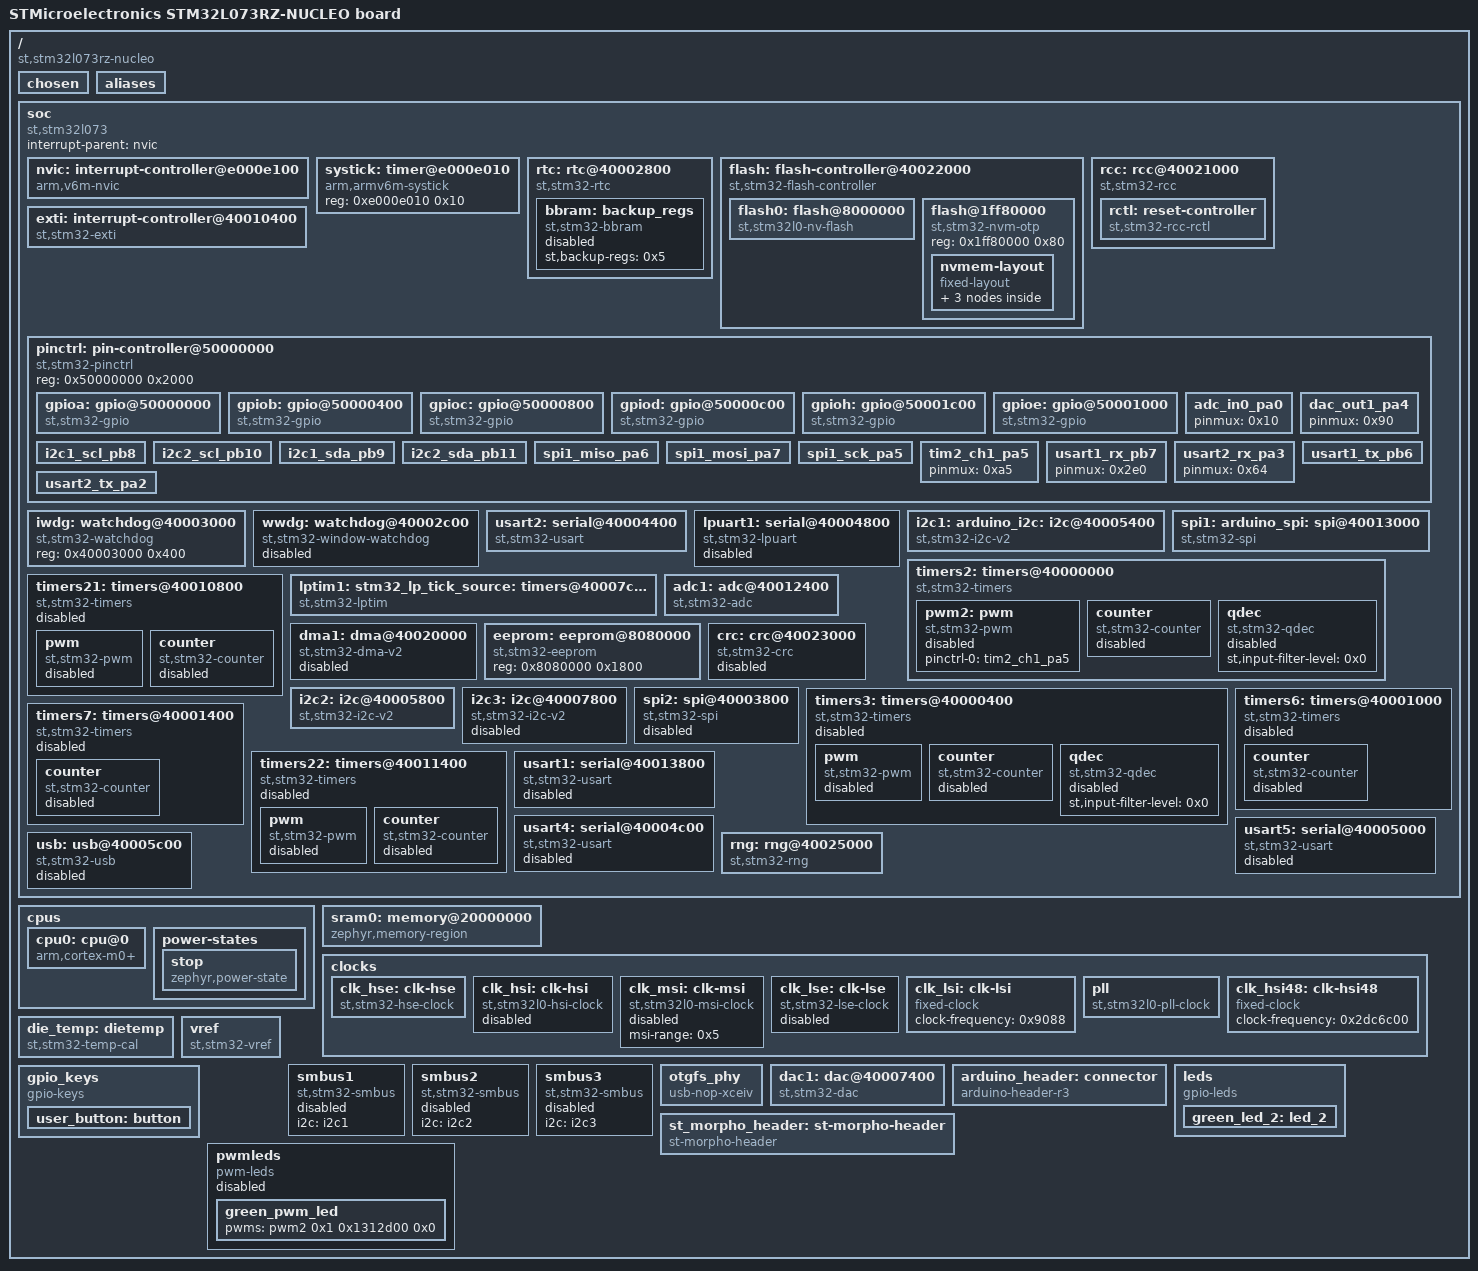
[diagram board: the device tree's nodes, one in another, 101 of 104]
/dts-v1/;

/* node '/' defined in zephyr/dts/common/skeleton.dtsi:9 */
/ {
	#address-cells = < 0x1 >;                              /* in zephyr/dts/common/skeleton.dtsi:10 */
	#size-cells = < 0x1 >;                                 /* in zephyr/dts/common/skeleton.dtsi:11 */
	model = "STMicroelectronics STM32L073RZ-NUCLEO board"; /* in zephyr/boards/st/nucleo_l073rz/nucleo_l073rz.dts:16 */
	compatible = "st,stm32l073rz-nucleo";                  /* in zephyr/boards/st/nucleo_l073rz/nucleo_l073rz.dts:17 */

	/* node '/chosen' defined in zephyr/dts/common/skeleton.dtsi:13 */
	chosen {
		zephyr,crc = &crc;                /* in zephyr/dts/arm/st/l0/stm32l0.dtsi:23 */
		zephyr,flash-controller = &flash; /* in zephyr/dts/arm/st/l0/stm32l0.dtsi:24 */
		zephyr,entropy = &rng;            /* in zephyr/dts/arm/st/l0/stm32l072.dtsi:11 */
		zephyr,console = &usart2;         /* in zephyr/boards/st/nucleo_l073rz/nucleo_l073rz.dts:20 */
		zephyr,shell-uart = &usart2;      /* in zephyr/boards/st/nucleo_l073rz/nucleo_l073rz.dts:21 */
		zephyr,sram = &sram0;             /* in zephyr/boards/st/nucleo_l073rz/nucleo_l073rz.dts:22 */
		zephyr,flash = &flash0;           /* in zephyr/boards/st/nucleo_l073rz/nucleo_l073rz.dts:23 */
	};

	/* node '/aliases' defined in zephyr/dts/common/skeleton.dtsi:15 */
	aliases {
		led0 = &green_led_2;       /* in zephyr/boards/st/nucleo_l073rz/nucleo_l073rz.dts:56 */
		sw0 = &user_button;        /* in zephyr/boards/st/nucleo_l073rz/nucleo_l073rz.dts:57 */
		pwm-led0 = &green_pwm_led; /* in zephyr/boards/st/nucleo_l073rz/nucleo_l073rz.dts:58 */
		watchdog0 = &iwdg;         /* in zephyr/boards/st/nucleo_l073rz/nucleo_l073rz.dts:59 */
		eeprom-0 = &eeprom;        /* in zephyr/boards/st/nucleo_l073rz/nucleo_l073rz.dts:60 */
		die-temp0 = &die_temp;     /* in zephyr/boards/st/nucleo_l073rz/nucleo_l073rz.dts:61 */
		volt-sensor0 = &vref;      /* in zephyr/boards/st/nucleo_l073rz/nucleo_l073rz.dts:62 */
	};

	/* node '/soc' defined in zephyr/dts/arm/armv6-m.dtsi:6 */
	soc {
		#address-cells = < 0x1 >;     /* in zephyr/dts/arm/armv6-m.dtsi:7 */
		#size-cells = < 0x1 >;        /* in zephyr/dts/arm/armv6-m.dtsi:8 */
		interrupt-parent = < &nvic >; /* in zephyr/dts/arm/armv6-m.dtsi:10 */
		ranges;                       /* in zephyr/dts/arm/armv6-m.dtsi:11 */
		compatible = "st,stm32l073",
		             "st,stm32l0",
		             "simple-bus";    /* in zephyr/dts/arm/st/l0/stm32l073.dtsi:12 */

		/* node '/soc/interrupt-controller@e000e100' defined in zephyr/dts/arm/armv6-m.dtsi:13 */
		nvic: interrupt-controller@e000e100 {
			#address-cells = < 0x1 >;            /* in zephyr/dts/arm/armv6-m.dtsi:14 */
			compatible = "arm,v6m-nvic";         /* in zephyr/dts/arm/armv6-m.dtsi:15 */
			reg = < 0xe000e100 0xc00 >;          /* in zephyr/dts/arm/armv6-m.dtsi:16 */
			interrupt-controller;                /* in zephyr/dts/arm/armv6-m.dtsi:17 */
			#interrupt-cells = < 0x2 >;          /* in zephyr/dts/arm/armv6-m.dtsi:18 */
			arm,num-irq-priority-bits = < 0x2 >; /* in zephyr/dts/arm/st/l0/stm32l0.dtsi:429 */
			phandle = < 0x1 >;                   /* in zephyr/dts/arm/armv6-m.dtsi:10 */
		};

		/* node '/soc/timer@e000e010' defined in zephyr/dts/arm/armv6-m.dtsi:21 */
		systick: timer@e000e010 {
			compatible = "arm,armv6m-systick"; /* in zephyr/dts/arm/armv6-m.dtsi:22 */
			reg = < 0xe000e010 0x10 >;         /* in zephyr/dts/arm/armv6-m.dtsi:23 */
		};

		/* node '/soc/rtc@40002800' defined in zephyr/dts/arm/st/l0/stm32l0.dtsi:98 */
		rtc: rtc@40002800 {
			compatible = "st,stm32-rtc";       /* in zephyr/dts/arm/st/l0/stm32l0.dtsi:99 */
			reg = < 0x40002800 0x400 >;        /* in zephyr/dts/arm/st/l0/stm32l0.dtsi:100 */
			interrupts = < 0x2 0x0 >;          /* in zephyr/dts/arm/st/l0/stm32l0.dtsi:101 */
			prescaler = < 0x8000 >;            /* in zephyr/dts/arm/st/l0/stm32l0.dtsi:103 */
			alarms-count = < 0x2 >;            /* in zephyr/dts/arm/st/l0/stm32l0.dtsi:104 */
			alrm-exti-line = < 0x11 >;         /* in zephyr/dts/arm/st/l0/stm32l0.dtsi:105 */
			clocks = < &rcc 0x38 0x10000000 >,
			         < &rcc 0x3 0x2300050 >;   /* in zephyr/boards/st/nucleo_l073rz/nucleo_l073rz.dts:172 */
			status = "okay";                   /* in zephyr/boards/st/nucleo_l073rz/nucleo_l073rz.dts:174 */

			/* node '/soc/rtc@40002800/backup_regs' defined in zephyr/dts/arm/st/l0/stm32l0.dtsi:108 */
			bbram: backup_regs {
				compatible = "st,stm32-bbram"; /* in zephyr/dts/arm/st/l0/stm32l0.dtsi:109 */
				st,backup-regs = < 0x5 >;      /* in zephyr/dts/arm/st/l0/stm32l0.dtsi:110 */
				status = "disabled";           /* in zephyr/dts/arm/st/l0/stm32l0.dtsi:111 */
			};
		};

		/* node '/soc/flash-controller@40022000' defined in zephyr/dts/arm/st/l0/stm32l0.dtsi:115 */
		flash: flash-controller@40022000 {
			compatible = "st,stm32-flash-controller",
			             "st,stm32f1-flash-controller"; /* in zephyr/dts/arm/st/l0/stm32l0.dtsi:116 */
			reg = < 0x40022000 0x400 >;                 /* in zephyr/dts/arm/st/l0/stm32l0.dtsi:117 */
			interrupts = < 0x3 0x0 >;                   /* in zephyr/dts/arm/st/l0/stm32l0.dtsi:118 */
			#address-cells = < 0x1 >;                   /* in zephyr/dts/arm/st/l0/stm32l0.dtsi:120 */
			#size-cells = < 0x1 >;                      /* in zephyr/dts/arm/st/l0/stm32l0.dtsi:121 */

			/* node '/soc/flash-controller@40022000/flash@8000000' defined in zephyr/dts/arm/st/l0/stm32l0.dtsi:123 */
			flash0: flash@8000000 {
				compatible = "st,stm32l0-nv-flash",
				             "st,stm32-nv-flash",
				             "soc-nv-flash";        /* in zephyr/dts/arm/st/l0/stm32l0.dtsi:124 */
				write-block-size = < 0x4 >;         /* in zephyr/dts/arm/st/l0/stm32l0.dtsi:127 */
				max-erase-time = < 0x4 >;           /* in zephyr/dts/arm/st/l0/stm32l0.dtsi:129 */
				reg = < 0x8000000 0x30000 >;        /* in zephyr/dts/arm/st/l0/stm32l073Xz.dtsi:17 */
			};

			/* node '/soc/flash-controller@40022000/flash@1ff80000' defined in zephyr/dts/arm/st/l0/stm32l0.dtsi:141 */
			flash@1ff80000 {
				compatible = "st,stm32-nvm-otp"; /* in zephyr/dts/arm/st/l0/stm32l0.dtsi:142 */
				reg = < 0x1ff80000 0x80 >;       /* in zephyr/dts/arm/st/l0/stm32l0.dtsi:143 */

				/* node '/soc/flash-controller@40022000/flash@1ff80000/nvmem-layout' defined in zephyr/dts/arm/st/l0/stm32l0.dtsi:145 */
				nvmem-layout {
					compatible = "fixed-layout"; /* in zephyr/dts/arm/st/l0/stm32l0.dtsi:146 */
					#address-cells = < 0x1 >;    /* in zephyr/dts/arm/st/l0/stm32l0.dtsi:147 */
					#size-cells = < 0x1 >;       /* in zephyr/dts/arm/st/l0/stm32l0.dtsi:148 */

					/* node '/soc/flash-controller@40022000/flash@1ff80000/nvmem-layout/vrefint@78' defined in zephyr/dts/arm/st/l0/stm32l0.dtsi:150 */
					vrefint_otp: vrefint@78 {
						reg = < 0x78 0x2 >;          /* in zephyr/dts/arm/st/l0/stm32l0.dtsi:151 */
						#nvmem-cell-cells = < 0x0 >; /* in zephyr/dts/arm/st/l0/stm32l0.dtsi:152 */
						read-only;                   /* in zephyr/dts/arm/st/l0/stm32l0.dtsi:153 */
						phandle = < 0x18 >;          /* in zephyr/dts/arm/st/l0/stm32l0.dtsi:413 */
					};

					/* node '/soc/flash-controller@40022000/flash@1ff80000/nvmem-layout/ts-cal1@7a' defined in zephyr/dts/arm/st/l0/stm32l0.dtsi:156 */
					ts_cal1_otp: ts-cal1@7a {
						reg = < 0x7a 0x2 >;          /* in zephyr/dts/arm/st/l0/stm32l0.dtsi:157 */
						#nvmem-cell-cells = < 0x0 >; /* in zephyr/dts/arm/st/l0/stm32l0.dtsi:158 */
						read-only;                   /* in zephyr/dts/arm/st/l0/stm32l0.dtsi:159 */
						phandle = < 0x15 >;          /* in zephyr/dts/arm/st/l0/stm32l0.dtsi:402 */
					};

					/* node '/soc/flash-controller@40022000/flash@1ff80000/nvmem-layout/ts-cal2@7e' defined in zephyr/dts/arm/st/l0/stm32l0.dtsi:162 */
					ts_cal2_otp: ts-cal2@7e {
						reg = < 0x7e 0x2 >;          /* in zephyr/dts/arm/st/l0/stm32l0.dtsi:163 */
						#nvmem-cell-cells = < 0x0 >; /* in zephyr/dts/arm/st/l0/stm32l0.dtsi:164 */
						read-only;                   /* in zephyr/dts/arm/st/l0/stm32l0.dtsi:165 */
						phandle = < 0x16 >;          /* in zephyr/dts/arm/st/l0/stm32l0.dtsi:402 */
					};
				};
			};
		};

		/* node '/soc/rcc@40021000' defined in zephyr/dts/arm/st/l0/stm32l0.dtsi:171 */
		rcc: rcc@40021000 {
			compatible = "st,stm32-rcc";     /* in zephyr/dts/arm/st/l0/stm32l0.dtsi:172 */
			#clock-cells = < 0x2 >;          /* in zephyr/dts/arm/st/l0/stm32l0.dtsi:173 */
			reg = < 0x40021000 0x400 >;      /* in zephyr/dts/arm/st/l0/stm32l0.dtsi:174 */
			clocks = < &pll >;               /* in zephyr/boards/st/nucleo_l073rz/nucleo_l073rz.dts:88 */
			clock-frequency = < 0x1e84800 >; /* in zephyr/boards/st/nucleo_l073rz/nucleo_l073rz.dts:89 */
			ahb-prescaler = < 0x1 >;         /* in zephyr/boards/st/nucleo_l073rz/nucleo_l073rz.dts:90 */
			apb1-prescaler = < 0x1 >;        /* in zephyr/boards/st/nucleo_l073rz/nucleo_l073rz.dts:91 */
			apb2-prescaler = < 0x1 >;        /* in zephyr/boards/st/nucleo_l073rz/nucleo_l073rz.dts:92 */
			phandle = < 0x2 >;               /* in zephyr/boards/st/nucleo_l073rz/nucleo_l073rz.dts:172 */

			/* node '/soc/rcc@40021000/reset-controller' defined in zephyr/dts/arm/st/l0/stm32l0.dtsi:176 */
			rctl: reset-controller {
				compatible = "st,stm32-rcc-rctl"; /* in zephyr/dts/arm/st/l0/stm32l0.dtsi:177 */
				#reset-cells = < 0x1 >;           /* in zephyr/dts/arm/st/l0/stm32l0.dtsi:178 */
				phandle = < 0x4 >;                /* in zephyr/dts/arm/st/l0/stm32l0.dtsi:260 */
			};
		};

		/* node '/soc/interrupt-controller@40010400' defined in zephyr/dts/arm/st/l0/stm32l0.dtsi:182 */
		exti: interrupt-controller@40010400 {
			compatible = "st,stm32-exti"; /* in zephyr/dts/arm/st/l0/stm32l0.dtsi:183 */
			interrupt-controller;         /* in zephyr/dts/arm/st/l0/stm32l0.dtsi:184 */
			#interrupt-cells = < 0x1 >;   /* in zephyr/dts/arm/st/l0/stm32l0.dtsi:185 */
			#address-cells = < 0x0 >;     /* in zephyr/dts/arm/st/l0/stm32l0.dtsi:186 */
			reg = < 0x40010400 0x400 >;   /* in zephyr/dts/arm/st/l0/stm32l0.dtsi:187 */
			clocks = < &rcc 0x34 0x1 >;   /* in zephyr/dts/arm/st/l0/stm32l0.dtsi:188 */
			num-lines = < 0x20 >;         /* in zephyr/dts/arm/st/l0/stm32l0.dtsi:189 */
			interrupts = < 0x5 0x0 >,
			             < 0x6 0x0 >,
			             < 0x7 0x0 >;     /* in zephyr/dts/arm/st/l0/stm32l0.dtsi:190 */
			interrupt-names = "line0-1",
			                  "line2-3",
			                  "line4-15"; /* in zephyr/dts/arm/st/l0/stm32l0.dtsi:191 */
			line-ranges = < 0x0 0x2 >,
			              < 0x2 0x2 >,
			              < 0x4 0xc >;    /* in zephyr/dts/arm/st/l0/stm32l0.dtsi:192 */
		};

		/* node '/soc/pin-controller@50000000' defined in zephyr/dts/arm/st/l0/stm32l0.dtsi:195 */
		pinctrl: pin-controller@50000000 {
			compatible = "st,stm32-pinctrl"; /* in zephyr/dts/arm/st/l0/stm32l0.dtsi:196 */
			#address-cells = < 0x1 >;        /* in zephyr/dts/arm/st/l0/stm32l0.dtsi:197 */
			#size-cells = < 0x1 >;           /* in zephyr/dts/arm/st/l0/stm32l0.dtsi:198 */
			reg = < 0x50000000 0x2000 >;     /* in zephyr/dts/arm/st/l0/stm32l0.dtsi:199 */

			/* node '/soc/pin-controller@50000000/gpio@50000000' defined in zephyr/dts/arm/st/l0/stm32l0.dtsi:201 */
			gpioa: gpio@50000000 {
				compatible = "st,stm32-gpio"; /* in zephyr/dts/arm/st/l0/stm32l0.dtsi:202 */
				gpio-controller;              /* in zephyr/dts/arm/st/l0/stm32l0.dtsi:203 */
				#gpio-cells = < 0x2 >;        /* in zephyr/dts/arm/st/l0/stm32l0.dtsi:204 */
				reg = < 0x50000000 0x400 >;   /* in zephyr/dts/arm/st/l0/stm32l0.dtsi:205 */
				clocks = < &rcc 0x2c 0x1 >;   /* in zephyr/dts/arm/st/l0/stm32l0.dtsi:206 */
				phandle = < 0x1d >;           /* in zephyr/boards/st/nucleo_l073rz/arduino_r3_connector.dtsi:15 */
			};

			/* node '/soc/pin-controller@50000000/gpio@50000400' defined in zephyr/dts/arm/st/l0/stm32l0.dtsi:209 */
			gpiob: gpio@50000400 {
				compatible = "st,stm32-gpio"; /* in zephyr/dts/arm/st/l0/stm32l0.dtsi:210 */
				gpio-controller;              /* in zephyr/dts/arm/st/l0/stm32l0.dtsi:211 */
				#gpio-cells = < 0x2 >;        /* in zephyr/dts/arm/st/l0/stm32l0.dtsi:212 */
				reg = < 0x50000400 0x400 >;   /* in zephyr/dts/arm/st/l0/stm32l0.dtsi:213 */
				clocks = < &rcc 0x2c 0x2 >;   /* in zephyr/dts/arm/st/l0/stm32l0.dtsi:214 */
				phandle = < 0x1e >;           /* in zephyr/boards/st/nucleo_l073rz/arduino_r3_connector.dtsi:15 */
			};

			/* node '/soc/pin-controller@50000000/gpio@50000800' defined in zephyr/dts/arm/st/l0/stm32l0.dtsi:217 */
			gpioc: gpio@50000800 {
				compatible = "st,stm32-gpio"; /* in zephyr/dts/arm/st/l0/stm32l0.dtsi:218 */
				gpio-controller;              /* in zephyr/dts/arm/st/l0/stm32l0.dtsi:219 */
				#gpio-cells = < 0x2 >;        /* in zephyr/dts/arm/st/l0/stm32l0.dtsi:220 */
				reg = < 0x50000800 0x400 >;   /* in zephyr/dts/arm/st/l0/stm32l0.dtsi:221 */
				clocks = < &rcc 0x2c 0x4 >;   /* in zephyr/dts/arm/st/l0/stm32l0.dtsi:222 */
				phandle = < 0x1f >;           /* in zephyr/boards/st/nucleo_l073rz/arduino_r3_connector.dtsi:15 */
			};

			/* node '/soc/pin-controller@50000000/gpio@50000c00' defined in zephyr/dts/arm/st/l0/stm32l0.dtsi:225 */
			gpiod: gpio@50000c00 {
				compatible = "st,stm32-gpio"; /* in zephyr/dts/arm/st/l0/stm32l0.dtsi:226 */
				gpio-controller;              /* in zephyr/dts/arm/st/l0/stm32l0.dtsi:227 */
				#gpio-cells = < 0x2 >;        /* in zephyr/dts/arm/st/l0/stm32l0.dtsi:228 */
				reg = < 0x50000c00 0x400 >;   /* in zephyr/dts/arm/st/l0/stm32l0.dtsi:229 */
				clocks = < &rcc 0x2c 0x8 >;   /* in zephyr/dts/arm/st/l0/stm32l0.dtsi:230 */
				phandle = < 0x20 >;           /* in zephyr/boards/st/nucleo_l073rz/st_morpho_connector.dtsi:15 */
			};

			/* node '/soc/pin-controller@50000000/gpio@50001c00' defined in zephyr/dts/arm/st/l0/stm32l0.dtsi:233 */
			gpioh: gpio@50001c00 {
				compatible = "st,stm32-gpio"; /* in zephyr/dts/arm/st/l0/stm32l0.dtsi:234 */
				gpio-controller;              /* in zephyr/dts/arm/st/l0/stm32l0.dtsi:235 */
				#gpio-cells = < 0x2 >;        /* in zephyr/dts/arm/st/l0/stm32l0.dtsi:236 */
				reg = < 0x50001c00 0x400 >;   /* in zephyr/dts/arm/st/l0/stm32l0.dtsi:237 */
				clocks = < &rcc 0x2c 0x80 >;  /* in zephyr/dts/arm/st/l0/stm32l0.dtsi:238 */
				phandle = < 0x21 >;           /* in zephyr/boards/st/nucleo_l073rz/st_morpho_connector.dtsi:15 */
			};

			/* node '/soc/pin-controller@50000000/gpio@50001000' defined in zephyr/dts/arm/st/l0/stm32l071.dtsi:14 */
			gpioe: gpio@50001000 {
				compatible = "st,stm32-gpio"; /* in zephyr/dts/arm/st/l0/stm32l071.dtsi:15 */
				gpio-controller;              /* in zephyr/dts/arm/st/l0/stm32l071.dtsi:16 */
				#gpio-cells = < 0x2 >;        /* in zephyr/dts/arm/st/l0/stm32l071.dtsi:17 */
				reg = < 0x50001000 0x400 >;   /* in zephyr/dts/arm/st/l0/stm32l071.dtsi:18 */
				clocks = < &rcc 0x2c 0x10 >;  /* in zephyr/dts/arm/st/l0/stm32l071.dtsi:19 */
			};

			/* node '/soc/pin-controller@50000000/adc_in0_pa0' defined in modules/hal/stm32/dts/st/l0/stm32l073r(b-z)tx-pinctrl.dtsi:13 */
			adc_in0_pa0: adc_in0_pa0 {
				pinmux = < 0x10 >; /* in modules/hal/stm32/dts/st/l0/stm32l073r(b-z)tx-pinctrl.dtsi:14 */
				phandle = < 0xd >; /* in zephyr/boards/st/nucleo_l073rz/nucleo_l073rz.dts:143 */
			};

			/* node '/soc/pin-controller@50000000/dac_out1_pa4' defined in modules/hal/stm32/dts/st/l0/stm32l073r(b-z)tx-pinctrl.dtsi:365 */
			dac_out1_pa4: dac_out1_pa4 {
				pinmux = < 0x90 >;  /* in modules/hal/stm32/dts/st/l0/stm32l073r(b-z)tx-pinctrl.dtsi:366 */
				phandle = < 0x1c >; /* in zephyr/boards/st/nucleo_l073rz/nucleo_l073rz.dts:156 */
			};

			/* node '/soc/pin-controller@50000000/i2c1_scl_pb8' defined in modules/hal/stm32/dts/st/l0/stm32l073r(b-z)tx-pinctrl.dtsi:387 */
			i2c1_scl_pb8: i2c1_scl_pb8 {
				pinmux = < 0x304 >; /* in modules/hal/stm32/dts/st/l0/stm32l073r(b-z)tx-pinctrl.dtsi:388 */
				bias-pull-up;       /* in modules/hal/stm32/dts/st/l0/stm32l073r(b-z)tx-pinctrl.dtsi:389 */
				drive-open-drain;   /* in modules/hal/stm32/dts/st/l0/stm32l073r(b-z)tx-pinctrl.dtsi:390 */
				phandle = < 0x7 >;  /* in zephyr/boards/st/nucleo_l073rz/nucleo_l073rz.dts:119 */
			};

			/* node '/soc/pin-controller@50000000/i2c2_scl_pb10' defined in modules/hal/stm32/dts/st/l0/stm32l073r(b-z)tx-pinctrl.dtsi:393 */
			i2c2_scl_pb10: i2c2_scl_pb10 {
				pinmux = < 0x346 >; /* in modules/hal/stm32/dts/st/l0/stm32l073r(b-z)tx-pinctrl.dtsi:394 */
				bias-pull-up;       /* in modules/hal/stm32/dts/st/l0/stm32l073r(b-z)tx-pinctrl.dtsi:395 */
				drive-open-drain;   /* in modules/hal/stm32/dts/st/l0/stm32l073r(b-z)tx-pinctrl.dtsi:396 */
				phandle = < 0xe >;  /* in zephyr/boards/st/nucleo_l073rz/nucleo_l073rz.dts:126 */
			};

			/* node '/soc/pin-controller@50000000/i2c1_sda_pb9' defined in modules/hal/stm32/dts/st/l0/stm32l073r(b-z)tx-pinctrl.dtsi:431 */
			i2c1_sda_pb9: i2c1_sda_pb9 {
				pinmux = < 0x324 >; /* in modules/hal/stm32/dts/st/l0/stm32l073r(b-z)tx-pinctrl.dtsi:432 */
				bias-pull-up;       /* in modules/hal/stm32/dts/st/l0/stm32l073r(b-z)tx-pinctrl.dtsi:433 */
				drive-open-drain;   /* in modules/hal/stm32/dts/st/l0/stm32l073r(b-z)tx-pinctrl.dtsi:434 */
				phandle = < 0x8 >;  /* in zephyr/boards/st/nucleo_l073rz/nucleo_l073rz.dts:119 */
			};

			/* node '/soc/pin-controller@50000000/i2c2_sda_pb11' defined in modules/hal/stm32/dts/st/l0/stm32l073r(b-z)tx-pinctrl.dtsi:437 */
			i2c2_sda_pb11: i2c2_sda_pb11 {
				pinmux = < 0x366 >; /* in modules/hal/stm32/dts/st/l0/stm32l073r(b-z)tx-pinctrl.dtsi:438 */
				bias-pull-up;       /* in modules/hal/stm32/dts/st/l0/stm32l073r(b-z)tx-pinctrl.dtsi:439 */
				drive-open-drain;   /* in modules/hal/stm32/dts/st/l0/stm32l073r(b-z)tx-pinctrl.dtsi:440 */
				phandle = < 0xf >;  /* in zephyr/boards/st/nucleo_l073rz/nucleo_l073rz.dts:126 */
			};

			/* node '/soc/pin-controller@50000000/spi1_miso_pa6' defined in modules/hal/stm32/dts/st/l0/stm32l073r(b-z)tx-pinctrl.dtsi:586 */
			spi1_miso_pa6: spi1_miso_pa6 {
				pinmux = < 0xc0 >;             /* in modules/hal/stm32/dts/st/l0/stm32l073r(b-z)tx-pinctrl.dtsi:587 */
				bias-pull-down;                /* in modules/hal/stm32/dts/st/l0/stm32l073r(b-z)tx-pinctrl.dtsi:588 */
				slew-rate = "very-high-speed"; /* in modules/hal/stm32/dts/st/l0/stm32l073r(b-z)tx-pinctrl.dtsi:589 */
				phandle = < 0xa >;             /* in zephyr/boards/st/nucleo_l073rz/nucleo_l073rz.dts:133 */
			};

			/* node '/soc/pin-controller@50000000/spi1_mosi_pa7' defined in modules/hal/stm32/dts/st/l0/stm32l073r(b-z)tx-pinctrl.dtsi:618 */
			spi1_mosi_pa7: spi1_mosi_pa7 {
				pinmux = < 0xe0 >;             /* in modules/hal/stm32/dts/st/l0/stm32l073r(b-z)tx-pinctrl.dtsi:619 */
				bias-pull-down;                /* in modules/hal/stm32/dts/st/l0/stm32l073r(b-z)tx-pinctrl.dtsi:620 */
				slew-rate = "very-high-speed"; /* in modules/hal/stm32/dts/st/l0/stm32l073r(b-z)tx-pinctrl.dtsi:621 */
				phandle = < 0xb >;             /* in zephyr/boards/st/nucleo_l073rz/nucleo_l073rz.dts:133 */
			};

			/* node '/soc/pin-controller@50000000/spi1_sck_pa5' defined in modules/hal/stm32/dts/st/l0/stm32l073r(b-z)tx-pinctrl.dtsi:676 */
			spi1_sck_pa5: spi1_sck_pa5 {
				pinmux = < 0xa0 >;             /* in modules/hal/stm32/dts/st/l0/stm32l073r(b-z)tx-pinctrl.dtsi:677 */
				bias-pull-down;                /* in modules/hal/stm32/dts/st/l0/stm32l073r(b-z)tx-pinctrl.dtsi:678 */
				slew-rate = "very-high-speed"; /* in modules/hal/stm32/dts/st/l0/stm32l073r(b-z)tx-pinctrl.dtsi:679 */
				phandle = < 0x9 >;             /* in zephyr/boards/st/nucleo_l073rz/nucleo_l073rz.dts:133 */
			};

			/* node '/soc/pin-controller@50000000/tim2_ch1_pa5' defined in modules/hal/stm32/dts/st/l0/stm32l073r(b-z)tx-pinctrl.dtsi:734 */
			tim2_ch1_pa5: tim2_ch1_pa5 {
				pinmux = < 0xa5 >; /* in modules/hal/stm32/dts/st/l0/stm32l073r(b-z)tx-pinctrl.dtsi:735 */
				phandle = < 0xc >; /* in zephyr/boards/st/nucleo_l073rz/nucleo_l073rz.dts:166 */
			};

			/* node '/soc/pin-controller@50000000/usart1_rx_pb7' defined in modules/hal/stm32/dts/st/l0/stm32l073r(b-z)tx-pinctrl.dtsi:1096 */
			usart1_rx_pb7: usart1_rx_pb7 {
				pinmux = < 0x2e0 >; /* in modules/hal/stm32/dts/st/l0/stm32l073r(b-z)tx-pinctrl.dtsi:1097 */
				phandle = < 0x11 >; /* in zephyr/boards/st/nucleo_l073rz/nucleo_l073rz.dts:106 */
			};

			/* node '/soc/pin-controller@50000000/usart2_rx_pa3' defined in modules/hal/stm32/dts/st/l0/stm32l073r(b-z)tx-pinctrl.dtsi:1120 */
			usart2_rx_pa3: usart2_rx_pa3 {
				pinmux = < 0x64 >; /* in modules/hal/stm32/dts/st/l0/stm32l073r(b-z)tx-pinctrl.dtsi:1121 */
				phandle = < 0x6 >; /* in zephyr/boards/st/nucleo_l073rz/nucleo_l073rz.dts:112 */
			};

			/* node '/soc/pin-controller@50000000/usart1_tx_pb6' defined in modules/hal/stm32/dts/st/l0/stm32l073r(b-z)tx-pinctrl.dtsi:1161 */
			usart1_tx_pb6: usart1_tx_pb6 {
				pinmux = < 0x2c0 >; /* in modules/hal/stm32/dts/st/l0/stm32l073r(b-z)tx-pinctrl.dtsi:1162 */
				bias-pull-up;       /* in modules/hal/stm32/dts/st/l0/stm32l073r(b-z)tx-pinctrl.dtsi:1163 */
				phandle = < 0x10 >; /* in zephyr/boards/st/nucleo_l073rz/nucleo_l073rz.dts:106 */
			};

			/* node '/soc/pin-controller@50000000/usart2_tx_pa2' defined in modules/hal/stm32/dts/st/l0/stm32l073r(b-z)tx-pinctrl.dtsi:1191 */
			usart2_tx_pa2: usart2_tx_pa2 {
				pinmux = < 0x44 >; /* in modules/hal/stm32/dts/st/l0/stm32l073r(b-z)tx-pinctrl.dtsi:1192 */
				bias-pull-up;      /* in modules/hal/stm32/dts/st/l0/stm32l073r(b-z)tx-pinctrl.dtsi:1193 */
				phandle = < 0x5 >; /* in zephyr/boards/st/nucleo_l073rz/nucleo_l073rz.dts:112 */
			};
		};

		/* node '/soc/watchdog@40003000' defined in zephyr/dts/arm/st/l0/stm32l0.dtsi:242 */
		iwdg: watchdog@40003000 {
			compatible = "st,stm32-watchdog"; /* in zephyr/dts/arm/st/l0/stm32l0.dtsi:243 */
			reg = < 0x40003000 0x400 >;       /* in zephyr/dts/arm/st/l0/stm32l0.dtsi:244 */
			status = "okay";                  /* in zephyr/boards/st/nucleo_l073rz/nucleo_l073rz.dts:139 */
		};

		/* node '/soc/watchdog@40002c00' defined in zephyr/dts/arm/st/l0/stm32l0.dtsi:248 */
		wwdg: watchdog@40002c00 {
			compatible = "st,stm32-window-watchdog"; /* in zephyr/dts/arm/st/l0/stm32l0.dtsi:249 */
			reg = < 0x40002c00 0x400 >;              /* in zephyr/dts/arm/st/l0/stm32l0.dtsi:250 */
			clocks = < &rcc 0x38 0x800 >;            /* in zephyr/dts/arm/st/l0/stm32l0.dtsi:251 */
			interrupts = < 0x0 0x2 >;                /* in zephyr/dts/arm/st/l0/stm32l0.dtsi:252 */
			status = "disabled";                     /* in zephyr/dts/arm/st/l0/stm32l0.dtsi:253 */
		};

		/* node '/soc/serial@40004400' defined in zephyr/dts/arm/st/l0/stm32l0.dtsi:256 */
		usart2: serial@40004400 {
			compatible = "st,stm32-usart",
			             "st,stm32-uart";                  /* in zephyr/dts/arm/st/l0/stm32l0.dtsi:257 */
			reg = < 0x40004400 0x400 >;                    /* in zephyr/dts/arm/st/l0/stm32l0.dtsi:258 */
			clocks = < &rcc 0x38 0x20000 >;                /* in zephyr/dts/arm/st/l0/stm32l0.dtsi:259 */
			resets = < &rctl 0x511 >;                      /* in zephyr/dts/arm/st/l0/stm32l0.dtsi:260 */
			interrupts = < 0x1c 0x0 >;                     /* in zephyr/dts/arm/st/l0/stm32l0.dtsi:261 */
			pinctrl-0 = < &usart2_tx_pa2 &usart2_rx_pa3 >; /* in zephyr/boards/st/nucleo_l073rz/nucleo_l073rz.dts:112 */
			pinctrl-names = "default";                     /* in zephyr/boards/st/nucleo_l073rz/nucleo_l073rz.dts:113 */
			current-speed = < 0x1c200 >;                   /* in zephyr/boards/st/nucleo_l073rz/nucleo_l073rz.dts:114 */
			status = "okay";                               /* in zephyr/boards/st/nucleo_l073rz/nucleo_l073rz.dts:115 */
		};

		/* node '/soc/serial@40004800' defined in zephyr/dts/arm/st/l0/stm32l0.dtsi:265 */
		lpuart1: serial@40004800 {
			compatible = "st,stm32-lpuart",
			             "st,stm32-uart";   /* in zephyr/dts/arm/st/l0/stm32l0.dtsi:266 */
			reg = < 0x40004800 0x400 >;     /* in zephyr/dts/arm/st/l0/stm32l0.dtsi:267 */
			clocks = < &rcc 0x38 0x40000 >; /* in zephyr/dts/arm/st/l0/stm32l0.dtsi:268 */
			resets = < &rctl 0x512 >;       /* in zephyr/dts/arm/st/l0/stm32l0.dtsi:269 */
			interrupts = < 0x1d 0x0 >;      /* in zephyr/dts/arm/st/l0/stm32l0.dtsi:270 */
			status = "disabled";            /* in zephyr/dts/arm/st/l0/stm32l0.dtsi:271 */
		};

		/* node '/soc/i2c@40005400' defined in zephyr/dts/arm/st/l0/stm32l0.dtsi:274 */
		i2c1: arduino_i2c: i2c@40005400 {
			compatible = "st,stm32-i2c-v2";              /* in zephyr/dts/arm/st/l0/stm32l0.dtsi:275 */
			#address-cells = < 0x1 >;                    /* in zephyr/dts/arm/st/l0/stm32l0.dtsi:277 */
			#size-cells = < 0x0 >;                       /* in zephyr/dts/arm/st/l0/stm32l0.dtsi:278 */
			reg = < 0x40005400 0x400 >;                  /* in zephyr/dts/arm/st/l0/stm32l0.dtsi:279 */
			clocks = < &rcc 0x38 0x200000 >;             /* in zephyr/dts/arm/st/l0/stm32l0.dtsi:280 */
			interrupts = < 0x17 0x0 >;                   /* in zephyr/dts/arm/st/l0/stm32l0.dtsi:281 */
			interrupt-names = "combined";                /* in zephyr/dts/arm/st/l0/stm32l0.dtsi:282 */
			pinctrl-0 = < &i2c1_scl_pb8 &i2c1_sda_pb9 >; /* in zephyr/boards/st/nucleo_l073rz/nucleo_l073rz.dts:119 */
			pinctrl-names = "default";                   /* in zephyr/boards/st/nucleo_l073rz/nucleo_l073rz.dts:120 */
			status = "okay";                             /* in zephyr/boards/st/nucleo_l073rz/nucleo_l073rz.dts:121 */
			clock-frequency = < 0x61a80 >;               /* in zephyr/boards/st/nucleo_l073rz/nucleo_l073rz.dts:122 */
			phandle = < 0x19 >;                          /* in zephyr/dts/arm/st/l0/stm32l0.dtsi:423 */
		};

		/* node '/soc/spi@40013000' defined in zephyr/dts/arm/st/l0/stm32l0.dtsi:286 */
		spi1: arduino_spi: spi@40013000 {
			compatible = "st,stm32-spi";                                 /* in zephyr/dts/arm/st/l0/stm32l0.dtsi:287 */
			#address-cells = < 0x1 >;                                    /* in zephyr/dts/arm/st/l0/stm32l0.dtsi:288 */
			#size-cells = < 0x0 >;                                       /* in zephyr/dts/arm/st/l0/stm32l0.dtsi:289 */
			reg = < 0x40013000 0x400 >;                                  /* in zephyr/dts/arm/st/l0/stm32l0.dtsi:290 */
			clocks = < &rcc 0x34 0x1000 >;                               /* in zephyr/dts/arm/st/l0/stm32l0.dtsi:291 */
			interrupts = < 0x19 0x3 >;                                   /* in zephyr/dts/arm/st/l0/stm32l0.dtsi:292 */
			st,spi-data-width = "limited-8-16-bit";                      /* in zephyr/dts/arm/st/l0/stm32l0.dtsi:293 */
			pinctrl-0 = < &spi1_sck_pa5 &spi1_miso_pa6 &spi1_mosi_pa7 >; /* in zephyr/boards/st/nucleo_l073rz/nucleo_l073rz.dts:133 */
			pinctrl-names = "default";                                   /* in zephyr/boards/st/nucleo_l073rz/nucleo_l073rz.dts:134 */
			status = "okay";                                             /* in zephyr/boards/st/nucleo_l073rz/nucleo_l073rz.dts:135 */
		};

		/* node '/soc/timers@40000000' defined in zephyr/dts/arm/st/l0/stm32l0.dtsi:297 */
		timers2: timers@40000000 {
			compatible = "st,stm32-timers"; /* in zephyr/dts/arm/st/l0/stm32l0.dtsi:298 */
			reg = < 0x40000000 0x400 >;     /* in zephyr/dts/arm/st/l0/stm32l0.dtsi:299 */
			clocks = < &rcc 0x38 0x1 >,
			         < &rcc 0x8 0xff >;     /* in zephyr/dts/arm/st/l0/stm32l0.dtsi:300 */
			resets = < &rctl 0x500 >;       /* in zephyr/dts/arm/st/l0/stm32l0.dtsi:302 */
			interrupts = < 0xf 0x0 >;       /* in zephyr/dts/arm/st/l0/stm32l0.dtsi:303 */
			interrupt-names = "global";     /* in zephyr/dts/arm/st/l0/stm32l0.dtsi:304 */
			st,prescaler = < 0x2710 >;      /* in zephyr/boards/st/nucleo_l073rz/nucleo_l073rz.dts:161 */
			status = "okay";                /* in zephyr/boards/st/nucleo_l073rz/nucleo_l073rz.dts:162 */

			/* node '/soc/timers@40000000/pwm' defined in zephyr/dts/arm/st/l0/stm32l0.dtsi:308 */
			pwm2: pwm {
				compatible = "st,stm32-pwm";   /* in zephyr/dts/arm/st/l0/stm32l0.dtsi:309 */
				status = "disabled";           /* in zephyr/dts/arm/st/l0/stm32l0.dtsi:310 */
				#pwm-cells = < 0x3 >;          /* in zephyr/dts/arm/st/l0/stm32l0.dtsi:311 */
				pinctrl-0 = < &tim2_ch1_pa5 >; /* in zephyr/boards/st/nucleo_l073rz/nucleo_l073rz.dts:166 */
				pinctrl-names = "default";     /* in zephyr/boards/st/nucleo_l073rz/nucleo_l073rz.dts:167 */
				phandle = < 0x22 >;            /* in zephyr/boards/st/nucleo_l073rz/nucleo_l073rz.dts:51 */
			};

			/* node '/soc/timers@40000000/counter' defined in zephyr/dts/arm/st/l0/stm32l0.dtsi:314 */
			counter {
				compatible = "st,stm32-counter"; /* in zephyr/dts/arm/st/l0/stm32l0.dtsi:315 */
				status = "disabled";             /* in zephyr/dts/arm/st/l0/stm32l0.dtsi:316 */
			};

			/* node '/soc/timers@40000000/qdec' defined in zephyr/dts/arm/st/l0/stm32l0.dtsi:319 */
			qdec {
				compatible = "st,stm32-qdec";    /* in zephyr/dts/arm/st/l0/stm32l0.dtsi:320 */
				st,input-filter-level = < 0x0 >; /* in zephyr/dts/arm/st/l0/stm32l0.dtsi:321 */
				status = "disabled";             /* in zephyr/dts/arm/st/l0/stm32l0.dtsi:322 */
			};
		};

		/* node '/soc/timers@40010800' defined in zephyr/dts/arm/st/l0/stm32l0.dtsi:326 */
		timers21: timers@40010800 {
			compatible = "st,stm32-timers"; /* in zephyr/dts/arm/st/l0/stm32l0.dtsi:327 */
			reg = < 0x40010800 0x400 >;     /* in zephyr/dts/arm/st/l0/stm32l0.dtsi:328 */
			clocks = < &rcc 0x34 0x4 >,
			         < &rcc 0x9 0xff >;     /* in zephyr/dts/arm/st/l0/stm32l0.dtsi:329 */
			resets = < &rctl 0x482 >;       /* in zephyr/dts/arm/st/l0/stm32l0.dtsi:331 */
			interrupts = < 0x14 0x0 >;      /* in zephyr/dts/arm/st/l0/stm32l0.dtsi:332 */
			interrupt-names = "global";     /* in zephyr/dts/arm/st/l0/stm32l0.dtsi:333 */
			st,prescaler = < 0x0 >;         /* in zephyr/dts/arm/st/l0/stm32l0.dtsi:334 */
			status = "disabled";            /* in zephyr/dts/arm/st/l0/stm32l0.dtsi:335 */

			/* node '/soc/timers@40010800/pwm' defined in zephyr/dts/arm/st/l0/stm32l0.dtsi:337 */
			pwm {
				compatible = "st,stm32-pwm"; /* in zephyr/dts/arm/st/l0/stm32l0.dtsi:338 */
				status = "disabled";         /* in zephyr/dts/arm/st/l0/stm32l0.dtsi:339 */
				#pwm-cells = < 0x3 >;        /* in zephyr/dts/arm/st/l0/stm32l0.dtsi:340 */
			};

			/* node '/soc/timers@40010800/counter' defined in zephyr/dts/arm/st/l0/stm32l0.dtsi:343 */
			counter {
				compatible = "st,stm32-counter"; /* in zephyr/dts/arm/st/l0/stm32l0.dtsi:344 */
				status = "disabled";             /* in zephyr/dts/arm/st/l0/stm32l0.dtsi:345 */
			};
		};

		/* node '/soc/timers@40007c00' defined in zephyr/dts/arm/st/l0/stm32l0.dtsi:349 */
		lptim1: stm32_lp_tick_source: timers@40007c00 {
			compatible = "st,stm32-lptim";     /* in zephyr/dts/arm/st/l0/stm32l0.dtsi:350 */
			resets = < &rctl 0x51f >;          /* in zephyr/dts/arm/st/l0/stm32l0.dtsi:352 */
			#address-cells = < 0x1 >;          /* in zephyr/dts/arm/st/l0/stm32l0.dtsi:353 */
			#size-cells = < 0x0 >;             /* in zephyr/dts/arm/st/l0/stm32l0.dtsi:354 */
			reg = < 0x40007c00 0x400 >;        /* in zephyr/dts/arm/st/l0/stm32l0.dtsi:355 */
			interrupts = < 0xd 0x1 >;          /* in zephyr/dts/arm/st/l0/stm32l0.dtsi:356 */
			interrupt-names = "wakeup";        /* in zephyr/dts/arm/st/l0/stm32l0.dtsi:357 */
			clocks = < &rcc 0x38 0x80000000 >,
			         < &rcc 0x3 0x132004c >;   /* in zephyr/boards/st/nucleo_l073rz/nucleo_l073rz.dts:100 */
			status = "okay";                   /* in zephyr/boards/st/nucleo_l073rz/nucleo_l073rz.dts:102 */
		};

		/* node '/soc/adc@40012400' defined in zephyr/dts/arm/st/l0/stm32l0.dtsi:361 */
		adc1: adc@40012400 {
			compatible = "st,stm32-adc";                              /* in zephyr/dts/arm/st/l0/stm32l0.dtsi:362 */
			reg = < 0x40012400 0x400 >;                               /* in zephyr/dts/arm/st/l0/stm32l0.dtsi:363 */
			clocks = < &rcc 0x34 0x200 >;                             /* in zephyr/dts/arm/st/l0/stm32l0.dtsi:364 */
			clock-names = "adcx";                                     /* in zephyr/dts/arm/st/l0/stm32l0.dtsi:365 */
			interrupts = < 0xc 0x0 >;                                 /* in zephyr/dts/arm/st/l0/stm32l0.dtsi:366 */
			#io-channel-cells = < 0x1 >;                              /* in zephyr/dts/arm/st/l0/stm32l0.dtsi:367 */
			st,adc-resolutions = < 0xc 0xa 0x8 0x6 >;                 /* in zephyr/dts/arm/st/l0/stm32l0.dtsi:368 */
			sampling-times = < 0x2 0x4 0x8 0xd 0x14 0x28 0x50 0xa1 >; /* in zephyr/dts/arm/st/l0/stm32l0.dtsi:369 */
			num-sampling-time-common-channels = < 0x1 >;              /* in zephyr/dts/arm/st/l0/stm32l0.dtsi:370 */
			st,adc-sequencer = "fixed";                               /* in zephyr/dts/arm/st/l0/stm32l0.dtsi:371 */
			st,adc-oversampler = "minimal";                           /* in zephyr/dts/arm/st/l0/stm32l0.dtsi:372 */
			st,adc-internal-regulator = "startup-sw-delay";           /* in zephyr/dts/arm/st/l0/stm32l0.dtsi:373 */
			pinctrl-0 = < &adc_in0_pa0 >;                             /* in zephyr/boards/st/nucleo_l073rz/nucleo_l073rz.dts:143 */
			pinctrl-names = "default";                                /* in zephyr/boards/st/nucleo_l073rz/nucleo_l073rz.dts:144 */
			st,adc-clock-source = "SYNC";                             /* in zephyr/boards/st/nucleo_l073rz/nucleo_l073rz.dts:145 */
			st,adc-prescaler = < 0x4 >;                               /* in zephyr/boards/st/nucleo_l073rz/nucleo_l073rz.dts:146 */
			status = "okay";                                          /* in zephyr/boards/st/nucleo_l073rz/nucleo_l073rz.dts:147 */
			phandle = < 0x17 >;                                       /* in zephyr/dts/arm/st/l0/stm32l0.dtsi:407 */
		};

		/* node '/soc/dma@40020000' defined in zephyr/dts/arm/st/l0/stm32l0.dtsi:377 */
		dma1: dma@40020000 {
			compatible = "st,stm32-dma-v2";                                           /* in zephyr/dts/arm/st/l0/stm32l0.dtsi:378 */
			#dma-cells = < 0x3 >;                                                     /* in zephyr/dts/arm/st/l0/stm32l0.dtsi:379 */
			reg = < 0x40020000 0x400 >;                                               /* in zephyr/dts/arm/st/l0/stm32l0.dtsi:380 */
			interrupts = < 0x9 0x0 0xa 0x0 0xa 0x0 0xb 0x0 0xb 0x0 0xb 0x0 0xb 0x0 >; /* in zephyr/dts/arm/st/l0/stm32l0.dtsi:381 */
			clocks = < &rcc 0x30 0x1 >;                                               /* in zephyr/dts/arm/st/l0/stm32l0.dtsi:382 */
			status = "disabled";                                                      /* in zephyr/dts/arm/st/l0/stm32l0.dtsi:383 */
		};

		/* node '/soc/eeprom@8080000' defined in zephyr/dts/arm/st/l0/stm32l0.dtsi:386 */
		eeprom: eeprom@8080000 {
			compatible = "st,stm32-eeprom"; /* in zephyr/dts/arm/st/l0/stm32l0.dtsi:387 */
			reg = < 0x8080000 0x1800 >;     /* in zephyr/dts/arm/st/l0/stm32l071.dtsi:172 */
			status = "okay";                /* in zephyr/boards/st/nucleo_l073rz/nucleo_l073rz.dts:182 */
		};

		/* node '/soc/crc@40023000' defined in zephyr/dts/arm/st/l0/stm32l0.dtsi:391 */
		crc: crc@40023000 {
			compatible = "st,stm32-crc";   /* in zephyr/dts/arm/st/l0/stm32l0.dtsi:392 */
			reg = < 0x40023000 0x400 >;    /* in zephyr/dts/arm/st/l0/stm32l0.dtsi:393 */
			clocks = < &rcc 0x30 0x1000 >; /* in zephyr/dts/arm/st/l0/stm32l0.dtsi:394 */
			resets = < &rctl 0x40c >;      /* in zephyr/dts/arm/st/l0/stm32l0.dtsi:395 */
			status = "disabled";           /* in zephyr/dts/arm/st/l0/stm32l0.dtsi:396 */
		};

		/* node '/soc/i2c@40005800' defined in zephyr/dts/arm/st/l0/stm32l071.dtsi:23 */
		i2c2: i2c@40005800 {
			compatible = "st,stm32-i2c-v2";                /* in zephyr/dts/arm/st/l0/stm32l071.dtsi:24 */
			#address-cells = < 0x1 >;                      /* in zephyr/dts/arm/st/l0/stm32l071.dtsi:26 */
			#size-cells = < 0x0 >;                         /* in zephyr/dts/arm/st/l0/stm32l071.dtsi:27 */
			reg = < 0x40005800 0x400 >;                    /* in zephyr/dts/arm/st/l0/stm32l071.dtsi:28 */
			clocks = < &rcc 0x38 0x400000 >;               /* in zephyr/dts/arm/st/l0/stm32l071.dtsi:29 */
			interrupts = < 0x18 0x0 >;                     /* in zephyr/dts/arm/st/l0/stm32l071.dtsi:30 */
			interrupt-names = "combined";                  /* in zephyr/dts/arm/st/l0/stm32l071.dtsi:31 */
			pinctrl-0 = < &i2c2_scl_pb10 &i2c2_sda_pb11 >; /* in zephyr/boards/st/nucleo_l073rz/nucleo_l073rz.dts:126 */
			pinctrl-names = "default";                     /* in zephyr/boards/st/nucleo_l073rz/nucleo_l073rz.dts:127 */
			status = "okay";                               /* in zephyr/boards/st/nucleo_l073rz/nucleo_l073rz.dts:128 */
			clock-frequency = < 0x61a80 >;                 /* in zephyr/boards/st/nucleo_l073rz/nucleo_l073rz.dts:129 */
			phandle = < 0x1a >;                            /* in zephyr/dts/arm/st/l0/stm32l071.dtsi:180 */
		};

		/* node '/soc/i2c@40007800' defined in zephyr/dts/arm/st/l0/stm32l071.dtsi:35 */
		i2c3: i2c@40007800 {
			compatible = "st,stm32-i2c-v2";    /* in zephyr/dts/arm/st/l0/stm32l071.dtsi:36 */
			clock-frequency = < 0x186a0 >;     /* in zephyr/dts/arm/st/l0/stm32l071.dtsi:37 */
			#address-cells = < 0x1 >;          /* in zephyr/dts/arm/st/l0/stm32l071.dtsi:38 */
			#size-cells = < 0x0 >;             /* in zephyr/dts/arm/st/l0/stm32l071.dtsi:39 */
			reg = < 0x40007800 0x400 >;        /* in zephyr/dts/arm/st/l0/stm32l071.dtsi:40 */
			clocks = < &rcc 0x38 0x40000000 >; /* in zephyr/dts/arm/st/l0/stm32l071.dtsi:41 */
			interrupts = < 0x15 0x0 >;         /* in zephyr/dts/arm/st/l0/stm32l071.dtsi:42 */
			interrupt-names = "combined";      /* in zephyr/dts/arm/st/l0/stm32l071.dtsi:43 */
			status = "disabled";               /* in zephyr/dts/arm/st/l0/stm32l071.dtsi:44 */
			phandle = < 0x1b >;                /* in zephyr/dts/arm/st/l0/stm32l071.dtsi:188 */
		};

		/* node '/soc/spi@40003800' defined in zephyr/dts/arm/st/l0/stm32l071.dtsi:47 */
		spi2: spi@40003800 {
			compatible = "st,stm32-spi";            /* in zephyr/dts/arm/st/l0/stm32l071.dtsi:48 */
			#address-cells = < 0x1 >;               /* in zephyr/dts/arm/st/l0/stm32l071.dtsi:49 */
			#size-cells = < 0x0 >;                  /* in zephyr/dts/arm/st/l0/stm32l071.dtsi:50 */
			reg = < 0x40003800 0x400 >;             /* in zephyr/dts/arm/st/l0/stm32l071.dtsi:51 */
			clocks = < &rcc 0x38 0x4000 >;          /* in zephyr/dts/arm/st/l0/stm32l071.dtsi:52 */
			interrupts = < 0x1a 0x3 >;              /* in zephyr/dts/arm/st/l0/stm32l071.dtsi:53 */
			st,spi-data-width = "limited-8-16-bit"; /* in zephyr/dts/arm/st/l0/stm32l071.dtsi:54 */
			status = "disabled";                    /* in zephyr/dts/arm/st/l0/stm32l071.dtsi:55 */
		};

		/* node '/soc/timers@40000400' defined in zephyr/dts/arm/st/l0/stm32l071.dtsi:58 */
		timers3: timers@40000400 {
			compatible = "st,stm32-timers"; /* in zephyr/dts/arm/st/l0/stm32l071.dtsi:59 */
			reg = < 0x40000400 0x400 >;     /* in zephyr/dts/arm/st/l0/stm32l071.dtsi:60 */
			clocks = < &rcc 0x38 0x2 >,
			         < &rcc 0x8 0xff >;     /* in zephyr/dts/arm/st/l0/stm32l071.dtsi:61 */
			resets = < &rctl 0x501 >;       /* in zephyr/dts/arm/st/l0/stm32l071.dtsi:63 */
			interrupts = < 0x10 0x0 >;      /* in zephyr/dts/arm/st/l0/stm32l071.dtsi:64 */
			interrupt-names = "global";     /* in zephyr/dts/arm/st/l0/stm32l071.dtsi:65 */
			st,prescaler = < 0x0 >;         /* in zephyr/dts/arm/st/l0/stm32l071.dtsi:66 */
			status = "disabled";            /* in zephyr/dts/arm/st/l0/stm32l071.dtsi:67 */

			/* node '/soc/timers@40000400/pwm' defined in zephyr/dts/arm/st/l0/stm32l071.dtsi:69 */
			pwm {
				compatible = "st,stm32-pwm"; /* in zephyr/dts/arm/st/l0/stm32l071.dtsi:70 */
				status = "disabled";         /* in zephyr/dts/arm/st/l0/stm32l071.dtsi:71 */
				#pwm-cells = < 0x3 >;        /* in zephyr/dts/arm/st/l0/stm32l071.dtsi:72 */
			};

			/* node '/soc/timers@40000400/counter' defined in zephyr/dts/arm/st/l0/stm32l071.dtsi:75 */
			counter {
				compatible = "st,stm32-counter"; /* in zephyr/dts/arm/st/l0/stm32l071.dtsi:76 */
				status = "disabled";             /* in zephyr/dts/arm/st/l0/stm32l071.dtsi:77 */
			};

			/* node '/soc/timers@40000400/qdec' defined in zephyr/dts/arm/st/l0/stm32l071.dtsi:80 */
			qdec {
				compatible = "st,stm32-qdec";    /* in zephyr/dts/arm/st/l0/stm32l071.dtsi:81 */
				st,input-filter-level = < 0x0 >; /* in zephyr/dts/arm/st/l0/stm32l071.dtsi:82 */
				status = "disabled";             /* in zephyr/dts/arm/st/l0/stm32l071.dtsi:83 */
			};
		};

		/* node '/soc/timers@40001000' defined in zephyr/dts/arm/st/l0/stm32l071.dtsi:87 */
		timers6: timers@40001000 {
			compatible = "st,stm32-timers"; /* in zephyr/dts/arm/st/l0/stm32l071.dtsi:88 */
			reg = < 0x40001000 0x400 >;     /* in zephyr/dts/arm/st/l0/stm32l071.dtsi:89 */
			clocks = < &rcc 0x38 0x10 >,
			         < &rcc 0x8 0xff >;     /* in zephyr/dts/arm/st/l0/stm32l071.dtsi:90 */
			resets = < &rctl 0x504 >;       /* in zephyr/dts/arm/st/l0/stm32l071.dtsi:92 */
			interrupts = < 0x11 0x0 >;      /* in zephyr/dts/arm/st/l0/stm32l071.dtsi:93 */
			interrupt-names = "global";     /* in zephyr/dts/arm/st/l0/stm32l071.dtsi:94 */
			st,prescaler = < 0x0 >;         /* in zephyr/dts/arm/st/l0/stm32l071.dtsi:95 */
			status = "disabled";            /* in zephyr/dts/arm/st/l0/stm32l071.dtsi:96 */

			/* node '/soc/timers@40001000/counter' defined in zephyr/dts/arm/st/l0/stm32l071.dtsi:98 */
			counter {
				compatible = "st,stm32-counter"; /* in zephyr/dts/arm/st/l0/stm32l071.dtsi:99 */
				status = "disabled";             /* in zephyr/dts/arm/st/l0/stm32l071.dtsi:100 */
			};
		};

		/* node '/soc/timers@40001400' defined in zephyr/dts/arm/st/l0/stm32l071.dtsi:104 */
		timers7: timers@40001400 {
			compatible = "st,stm32-timers"; /* in zephyr/dts/arm/st/l0/stm32l071.dtsi:105 */
			reg = < 0x40001400 0x400 >;     /* in zephyr/dts/arm/st/l0/stm32l071.dtsi:106 */
			clocks = < &rcc 0x38 0x20 >,
			         < &rcc 0x8 0xff >;     /* in zephyr/dts/arm/st/l0/stm32l071.dtsi:107 */
			resets = < &rctl 0x505 >;       /* in zephyr/dts/arm/st/l0/stm32l071.dtsi:109 */
			interrupts = < 0x12 0x0 >;      /* in zephyr/dts/arm/st/l0/stm32l071.dtsi:110 */
			interrupt-names = "global";     /* in zephyr/dts/arm/st/l0/stm32l071.dtsi:111 */
			st,prescaler = < 0x0 >;         /* in zephyr/dts/arm/st/l0/stm32l071.dtsi:112 */
			status = "disabled";            /* in zephyr/dts/arm/st/l0/stm32l071.dtsi:113 */

			/* node '/soc/timers@40001400/counter' defined in zephyr/dts/arm/st/l0/stm32l071.dtsi:115 */
			counter {
				compatible = "st,stm32-counter"; /* in zephyr/dts/arm/st/l0/stm32l071.dtsi:116 */
				status = "disabled";             /* in zephyr/dts/arm/st/l0/stm32l071.dtsi:117 */
			};
		};

		/* node '/soc/timers@40011400' defined in zephyr/dts/arm/st/l0/stm32l071.dtsi:121 */
		timers22: timers@40011400 {
			compatible = "st,stm32-timers"; /* in zephyr/dts/arm/st/l0/stm32l071.dtsi:122 */
			reg = < 0x40011400 0x400 >;     /* in zephyr/dts/arm/st/l0/stm32l071.dtsi:123 */
			clocks = < &rcc 0x34 0x20 >,
			         < &rcc 0x9 0xff >;     /* in zephyr/dts/arm/st/l0/stm32l071.dtsi:124 */
			resets = < &rctl 0x485 >;       /* in zephyr/dts/arm/st/l0/stm32l071.dtsi:126 */
			interrupts = < 0x16 0x0 >;      /* in zephyr/dts/arm/st/l0/stm32l071.dtsi:127 */
			interrupt-names = "global";     /* in zephyr/dts/arm/st/l0/stm32l071.dtsi:128 */
			st,prescaler = < 0x0 >;         /* in zephyr/dts/arm/st/l0/stm32l071.dtsi:129 */
			status = "disabled";            /* in zephyr/dts/arm/st/l0/stm32l071.dtsi:130 */

			/* node '/soc/timers@40011400/pwm' defined in zephyr/dts/arm/st/l0/stm32l071.dtsi:132 */
			pwm {
				compatible = "st,stm32-pwm"; /* in zephyr/dts/arm/st/l0/stm32l071.dtsi:133 */
				status = "disabled";         /* in zephyr/dts/arm/st/l0/stm32l071.dtsi:134 */
				#pwm-cells = < 0x3 >;        /* in zephyr/dts/arm/st/l0/stm32l071.dtsi:135 */
			};

			/* node '/soc/timers@40011400/counter' defined in zephyr/dts/arm/st/l0/stm32l071.dtsi:138 */
			counter {
				compatible = "st,stm32-counter"; /* in zephyr/dts/arm/st/l0/stm32l071.dtsi:139 */
				status = "disabled";             /* in zephyr/dts/arm/st/l0/stm32l071.dtsi:140 */
			};
		};

		/* node '/soc/serial@40013800' defined in zephyr/dts/arm/st/l0/stm32l071.dtsi:144 */
		usart1: serial@40013800 {
			compatible = "st,stm32-usart",
			             "st,stm32-uart";                  /* in zephyr/dts/arm/st/l0/stm32l071.dtsi:145 */
			reg = < 0x40013800 0x400 >;                    /* in zephyr/dts/arm/st/l0/stm32l071.dtsi:146 */
			clocks = < &rcc 0x34 0x4000 >;                 /* in zephyr/dts/arm/st/l0/stm32l071.dtsi:147 */
			resets = < &rctl 0x48e >;                      /* in zephyr/dts/arm/st/l0/stm32l071.dtsi:148 */
			interrupts = < 0x1b 0x0 >;                     /* in zephyr/dts/arm/st/l0/stm32l071.dtsi:149 */
			status = "disabled";                           /* in zephyr/dts/arm/st/l0/stm32l071.dtsi:150 */
			pinctrl-0 = < &usart1_tx_pb6 &usart1_rx_pb7 >; /* in zephyr/boards/st/nucleo_l073rz/nucleo_l073rz.dts:106 */
			pinctrl-names = "default";                     /* in zephyr/boards/st/nucleo_l073rz/nucleo_l073rz.dts:107 */
			current-speed = < 0x1c200 >;                   /* in zephyr/boards/st/nucleo_l073rz/nucleo_l073rz.dts:108 */
		};

		/* node '/soc/serial@40004c00' defined in zephyr/dts/arm/st/l0/stm32l071.dtsi:153 */
		usart4: serial@40004c00 {
			compatible = "st,stm32-usart",
			             "st,stm32-uart";   /* in zephyr/dts/arm/st/l0/stm32l071.dtsi:154 */
			reg = < 0x40004c00 0x400 >;     /* in zephyr/dts/arm/st/l0/stm32l071.dtsi:155 */
			clocks = < &rcc 0x38 0x80000 >; /* in zephyr/dts/arm/st/l0/stm32l071.dtsi:156 */
			resets = < &rctl 0x513 >;       /* in zephyr/dts/arm/st/l0/stm32l071.dtsi:157 */
			interrupts = < 0xe 0x0 >;       /* in zephyr/dts/arm/st/l0/stm32l071.dtsi:158 */
			status = "disabled";            /* in zephyr/dts/arm/st/l0/stm32l071.dtsi:159 */
		};

		/* node '/soc/serial@40005000' defined in zephyr/dts/arm/st/l0/stm32l071.dtsi:162 */
		usart5: serial@40005000 {
			compatible = "st,stm32-usart",
			             "st,stm32-uart";    /* in zephyr/dts/arm/st/l0/stm32l071.dtsi:163 */
			reg = < 0x40005000 0x400 >;      /* in zephyr/dts/arm/st/l0/stm32l071.dtsi:164 */
			clocks = < &rcc 0x38 0x100000 >; /* in zephyr/dts/arm/st/l0/stm32l071.dtsi:165 */
			resets = < &rctl 0x514 >;        /* in zephyr/dts/arm/st/l0/stm32l071.dtsi:166 */
			interrupts = < 0xe 0x0 >;        /* in zephyr/dts/arm/st/l0/stm32l071.dtsi:167 */
			status = "disabled";             /* in zephyr/dts/arm/st/l0/stm32l071.dtsi:168 */
		};

		/* node '/soc/usb@40005c00' defined in zephyr/dts/arm/st/l0/stm32l072.dtsi:26 */
		usb: usb@40005c00 {
			compatible = "st,stm32-usb";     /* in zephyr/dts/arm/st/l0/stm32l072.dtsi:27 */
			reg = < 0x40005c00 0x400 >;      /* in zephyr/dts/arm/st/l0/stm32l072.dtsi:28 */
			interrupts = < 0x1f 0x0 >;       /* in zephyr/dts/arm/st/l0/stm32l072.dtsi:29 */
			interrupt-names = "usb";         /* in zephyr/dts/arm/st/l0/stm32l072.dtsi:30 */
			num-bidir-endpoints = < 0x8 >;   /* in zephyr/dts/arm/st/l0/stm32l072.dtsi:31 */
			ram-size = < 0x400 >;            /* in zephyr/dts/arm/st/l0/stm32l072.dtsi:32 */
			maximum-speed = "full-speed";    /* in zephyr/dts/arm/st/l0/stm32l072.dtsi:33 */
			phys = < &otgfs_phy >;           /* in zephyr/dts/arm/st/l0/stm32l072.dtsi:34 */
			clocks = < &rcc 0x38 0x800000 >,
			         < &rcc 0x6 0x11a004c >; /* in zephyr/dts/arm/st/l0/stm32l072.dtsi:35 */
			status = "disabled";             /* in zephyr/dts/arm/st/l0/stm32l072.dtsi:37 */
		};

		/* node '/soc/rng@40025000' defined in zephyr/dts/arm/st/l0/stm32l072.dtsi:40 */
		rng: rng@40025000 {
			compatible = "st,stm32-rng";     /* in zephyr/dts/arm/st/l0/stm32l072.dtsi:41 */
			reg = < 0x40025000 0x400 >;      /* in zephyr/dts/arm/st/l0/stm32l072.dtsi:42 */
			interrupts = < 0x1d 0x0 >;       /* in zephyr/dts/arm/st/l0/stm32l072.dtsi:43 */
			clocks = < &rcc 0x30 0x100000 >; /* in zephyr/dts/arm/st/l0/stm32l072.dtsi:44 */
			status = "okay";                 /* in zephyr/boards/st/nucleo_l073rz/nucleo_l073rz.dts:178 */
		};
	};

	/* node '/cpus' defined in zephyr/dts/arm/st/l0/stm32l0.dtsi:27 */
	cpus {
		#address-cells = < 0x1 >; /* in zephyr/dts/arm/st/l0/stm32l0.dtsi:28 */
		#size-cells = < 0x0 >;    /* in zephyr/dts/arm/st/l0/stm32l0.dtsi:29 */

		/* node '/cpus/cpu@0' defined in zephyr/dts/arm/st/l0/stm32l0.dtsi:31 */
		cpu0: cpu@0 {
			device_type = "cpu";           /* in zephyr/dts/arm/st/l0/stm32l0.dtsi:32 */
			compatible = "arm,cortex-m0+"; /* in zephyr/dts/arm/st/l0/stm32l0.dtsi:33 */
			reg = < 0x0 >;                 /* in zephyr/dts/arm/st/l0/stm32l0.dtsi:34 */
			cpu-power-states = < &stop >;  /* in zephyr/dts/arm/st/l0/stm32l0.dtsi:35 */
		};

		/* node '/cpus/power-states' defined in zephyr/dts/arm/st/l0/stm32l0.dtsi:38 */
		power-states {

			/* node '/cpus/power-states/stop' defined in zephyr/dts/arm/st/l0/stm32l0.dtsi:39 */
			stop: stop {
				compatible = "zephyr,power-state";    /* in zephyr/dts/arm/st/l0/stm32l0.dtsi:40 */
				power-state-name = "suspend-to-idle"; /* in zephyr/dts/arm/st/l0/stm32l0.dtsi:41 */
				min-residency-us = < 0x7d0 >;         /* in zephyr/dts/arm/st/l0/stm32l0.dtsi:42 */
				exit-latency-us = < 0x2ee >;          /* in zephyr/dts/arm/st/l0/stm32l0.dtsi:43 */
				phandle = < 0x13 >;                   /* in zephyr/dts/arm/st/l0/stm32l0.dtsi:35 */
			};
		};
	};

	/* node '/memory@20000000' defined in zephyr/dts/arm/st/l0/stm32l0.dtsi:48 */
	sram0: memory@20000000 {
		compatible = "zephyr,memory-region",
		             "mmio-sram";            /* in zephyr/dts/arm/st/l0/stm32l0.dtsi:49 */
		zephyr,memory-region = "SRAM0";      /* in zephyr/dts/arm/st/l0/stm32l0.dtsi:50 */
		reg = < 0x20000000 0x5000 >;         /* in zephyr/dts/arm/st/l0/stm32l073Xz.dtsi:11 */
	};

	/* node '/clocks' defined in zephyr/dts/arm/st/l0/stm32l0.dtsi:53 */
	clocks {

		/* node '/clocks/clk-hse' defined in zephyr/dts/arm/st/l0/stm32l0.dtsi:54 */
		clk_hse: clk-hse {
			#clock-cells = < 0x0 >;            /* in zephyr/dts/arm/st/l0/stm32l0.dtsi:55 */
			compatible = "st,stm32-hse-clock"; /* in zephyr/dts/arm/st/l0/stm32l0.dtsi:56 */
			hse-bypass;                        /* in zephyr/boards/st/nucleo_l073rz/nucleo_l073rz.dts:67 */
			clock-frequency = < 0x7a1200 >;    /* in zephyr/boards/st/nucleo_l073rz/nucleo_l073rz.dts:68 */
			status = "okay";                   /* in zephyr/boards/st/nucleo_l073rz/nucleo_l073rz.dts:69 */
			phandle = < 0x14 >;                /* in zephyr/boards/st/nucleo_l073rz/nucleo_l073rz.dts:83 */
		};

		/* node '/clocks/clk-hsi' defined in zephyr/dts/arm/st/l0/stm32l0.dtsi:60 */
		clk_hsi: clk-hsi {
			#clock-cells = < 0x0 >;              /* in zephyr/dts/arm/st/l0/stm32l0.dtsi:61 */
			compatible = "st,stm32l0-hsi-clock"; /* in zephyr/dts/arm/st/l0/stm32l0.dtsi:62 */
			clock-frequency = < 0xf42400 >;      /* in zephyr/dts/arm/st/l0/stm32l0.dtsi:63 */
			hsi-div = < 0x1 >;                   /* in zephyr/dts/arm/st/l0/stm32l0.dtsi:64 */
			status = "disabled";                 /* in zephyr/dts/arm/st/l0/stm32l0.dtsi:65 */
		};

		/* node '/clocks/clk-msi' defined in zephyr/dts/arm/st/l0/stm32l0.dtsi:68 */
		clk_msi: clk-msi {
			#clock-cells = < 0x0 >;              /* in zephyr/dts/arm/st/l0/stm32l0.dtsi:69 */
			compatible = "st,stm32l0-msi-clock"; /* in zephyr/dts/arm/st/l0/stm32l0.dtsi:70 */
			msi-range = < 0x5 >;                 /* in zephyr/dts/arm/st/l0/stm32l0.dtsi:71 */
			status = "disabled";                 /* in zephyr/dts/arm/st/l0/stm32l0.dtsi:72 */
		};

		/* node '/clocks/clk-lse' defined in zephyr/dts/arm/st/l0/stm32l0.dtsi:75 */
		clk_lse: clk-lse {
			#clock-cells = < 0x0 >;            /* in zephyr/dts/arm/st/l0/stm32l0.dtsi:76 */
			compatible = "st,stm32-lse-clock"; /* in zephyr/dts/arm/st/l0/stm32l0.dtsi:77 */
			clock-frequency = < 0x8000 >;      /* in zephyr/dts/arm/st/l0/stm32l0.dtsi:78 */
			driving-capability = < 0x0 >;      /* in zephyr/dts/arm/st/l0/stm32l0.dtsi:79 */
			status = "disabled";               /* in zephyr/dts/arm/st/l0/stm32l0.dtsi:80 */
		};

		/* node '/clocks/clk-lsi' defined in zephyr/dts/arm/st/l0/stm32l0.dtsi:83 */
		clk_lsi: clk-lsi {
			#clock-cells = < 0x0 >;       /* in zephyr/dts/arm/st/l0/stm32l0.dtsi:84 */
			compatible = "fixed-clock";   /* in zephyr/dts/arm/st/l0/stm32l0.dtsi:85 */
			clock-frequency = < 0x9088 >; /* in zephyr/dts/arm/st/l0/stm32l0.dtsi:86 */
			status = "okay";              /* in zephyr/boards/st/nucleo_l073rz/nucleo_l073rz.dts:73 */
		};

		/* node '/clocks/pll' defined in zephyr/dts/arm/st/l0/stm32l0.dtsi:90 */
		pll: pll {
			#clock-cells = < 0x0 >;              /* in zephyr/dts/arm/st/l0/stm32l0.dtsi:91 */
			compatible = "st,stm32l0-pll-clock"; /* in zephyr/dts/arm/st/l0/stm32l0.dtsi:92 */
			div = < 0x2 >;                       /* in zephyr/boards/st/nucleo_l073rz/nucleo_l073rz.dts:81 */
			mul = < 0x8 >;                       /* in zephyr/boards/st/nucleo_l073rz/nucleo_l073rz.dts:82 */
			clocks = < &clk_hse >;               /* in zephyr/boards/st/nucleo_l073rz/nucleo_l073rz.dts:83 */
			status = "okay";                     /* in zephyr/boards/st/nucleo_l073rz/nucleo_l073rz.dts:84 */
			phandle = < 0x3 >;                   /* in zephyr/boards/st/nucleo_l073rz/nucleo_l073rz.dts:88 */
		};

		/* node '/clocks/clk-hsi48' defined in zephyr/dts/arm/st/l0/stm32l072.dtsi:15 */
		clk_hsi48: clk-hsi48 {
			#clock-cells = < 0x0 >;          /* in zephyr/dts/arm/st/l0/stm32l072.dtsi:16 */
			compatible = "fixed-clock";      /* in zephyr/dts/arm/st/l0/stm32l072.dtsi:17 */
			clock-frequency = < 0x2dc6c00 >; /* in zephyr/dts/arm/st/l0/stm32l072.dtsi:18 */
			status = "okay";                 /* in zephyr/boards/st/nucleo_l073rz/nucleo_l073rz.dts:77 */
		};
	};

	/* node '/dietemp' defined in zephyr/dts/arm/st/l0/stm32l0.dtsi:400 */
	die_temp: dietemp {
		compatible = "st,stm32-temp-cal"; /* in zephyr/dts/arm/st/l0/stm32l0.dtsi:401 */
		nvmem-cells = < &ts_cal1_otp >,
		              < &ts_cal2_otp >;   /* in zephyr/dts/arm/st/l0/stm32l0.dtsi:402 */
		nvmem-cell-names = "TS_CAL1",
		                   "TS_CAL2";     /* in zephyr/dts/arm/st/l0/stm32l0.dtsi:403 */
		ts-cal1-temp = < 0x1e >;          /* in zephyr/dts/arm/st/l0/stm32l0.dtsi:404 */
		ts-cal2-temp = < 0x82 >;          /* in zephyr/dts/arm/st/l0/stm32l0.dtsi:405 */
		ts-cal-vrefanalog = < 0xbb8 >;    /* in zephyr/dts/arm/st/l0/stm32l0.dtsi:406 */
		io-channels = < &adc1 0x12 >;     /* in zephyr/dts/arm/st/l0/stm32l0.dtsi:407 */
		status = "okay";                  /* in zephyr/boards/st/nucleo_l073rz/nucleo_l073rz.dts:151 */
	};

	/* node '/vref' defined in zephyr/dts/arm/st/l0/stm32l0.dtsi:411 */
	vref: vref {
		compatible = "st,stm32-vref";   /* in zephyr/dts/arm/st/l0/stm32l0.dtsi:412 */
		nvmem-cells = < &vrefint_otp >; /* in zephyr/dts/arm/st/l0/stm32l0.dtsi:413 */
		vrefint-cal-mv = < 0xbb8 >;     /* in zephyr/dts/arm/st/l0/stm32l0.dtsi:414 */
		io-channels = < &adc1 0x11 >;   /* in zephyr/dts/arm/st/l0/stm32l0.dtsi:415 */
		status = "okay";                /* in zephyr/boards/st/nucleo_l073rz/nucleo_l073rz.dts:186 */
	};

	/* node '/smbus1' defined in zephyr/dts/arm/st/l0/stm32l0.dtsi:419 */
	smbus1: smbus1 {
		compatible = "st,stm32-smbus"; /* in zephyr/dts/arm/st/l0/stm32l0.dtsi:420 */
		#address-cells = < 0x1 >;      /* in zephyr/dts/arm/st/l0/stm32l0.dtsi:421 */
		#size-cells = < 0x0 >;         /* in zephyr/dts/arm/st/l0/stm32l0.dtsi:422 */
		i2c = < &i2c1 >;               /* in zephyr/dts/arm/st/l0/stm32l0.dtsi:423 */
		status = "disabled";           /* in zephyr/dts/arm/st/l0/stm32l0.dtsi:424 */
	};

	/* node '/smbus2' defined in zephyr/dts/arm/st/l0/stm32l071.dtsi:176 */
	smbus2: smbus2 {
		compatible = "st,stm32-smbus"; /* in zephyr/dts/arm/st/l0/stm32l071.dtsi:177 */
		#address-cells = < 0x1 >;      /* in zephyr/dts/arm/st/l0/stm32l071.dtsi:178 */
		#size-cells = < 0x0 >;         /* in zephyr/dts/arm/st/l0/stm32l071.dtsi:179 */
		i2c = < &i2c2 >;               /* in zephyr/dts/arm/st/l0/stm32l071.dtsi:180 */
		status = "disabled";           /* in zephyr/dts/arm/st/l0/stm32l071.dtsi:181 */
	};

	/* node '/smbus3' defined in zephyr/dts/arm/st/l0/stm32l071.dtsi:184 */
	smbus3: smbus3 {
		compatible = "st,stm32-smbus"; /* in zephyr/dts/arm/st/l0/stm32l071.dtsi:185 */
		#address-cells = < 0x1 >;      /* in zephyr/dts/arm/st/l0/stm32l071.dtsi:186 */
		#size-cells = < 0x0 >;         /* in zephyr/dts/arm/st/l0/stm32l071.dtsi:187 */
		i2c = < &i2c3 >;               /* in zephyr/dts/arm/st/l0/stm32l071.dtsi:188 */
		status = "disabled";           /* in zephyr/dts/arm/st/l0/stm32l071.dtsi:189 */
	};

	/* node '/otgfs_phy' defined in zephyr/dts/arm/st/l0/stm32l072.dtsi:49 */
	otgfs_phy: otgfs_phy {
		compatible = "usb-nop-xceiv"; /* in zephyr/dts/arm/st/l0/stm32l072.dtsi:50 */
		#phy-cells = < 0x0 >;         /* in zephyr/dts/arm/st/l0/stm32l072.dtsi:51 */
		phandle = < 0x12 >;           /* in zephyr/dts/arm/st/l0/stm32l072.dtsi:34 */
	};

	/* node '/dac@40007400' defined in zephyr/dts/arm/st/l0/stm32l072.dtsi:54 */
	dac1: dac@40007400 {
		compatible = "st,stm32-dac";       /* in zephyr/dts/arm/st/l0/stm32l072.dtsi:55 */
		reg = < 0x40007400 0x400 >;        /* in zephyr/dts/arm/st/l0/stm32l072.dtsi:56 */
		clocks = < &rcc 0x38 0x20000000 >; /* in zephyr/dts/arm/st/l0/stm32l072.dtsi:57 */
		#io-channel-cells = < 0x1 >;       /* in zephyr/dts/arm/st/l0/stm32l072.dtsi:59 */
		status = "okay";                   /* in zephyr/boards/st/nucleo_l073rz/nucleo_l073rz.dts:155 */
		pinctrl-0 = < &dac_out1_pa4 >;     /* in zephyr/boards/st/nucleo_l073rz/nucleo_l073rz.dts:156 */
		pinctrl-names = "default";         /* in zephyr/boards/st/nucleo_l073rz/nucleo_l073rz.dts:157 */
	};

	/* node '/connector' defined in zephyr/boards/st/nucleo_l073rz/arduino_r3_connector.dtsi:10 */
	arduino_header: connector {
		compatible = "arduino-header-r3";          /* in zephyr/boards/st/nucleo_l073rz/arduino_r3_connector.dtsi:11 */
		#gpio-cells = < 0x2 >;                     /* in zephyr/boards/st/nucleo_l073rz/arduino_r3_connector.dtsi:12 */
		gpio-map-mask = < 0xffffffff 0xffffffc0 >; /* in zephyr/boards/st/nucleo_l073rz/arduino_r3_connector.dtsi:13 */
		gpio-map-pass-thru = < 0x0 0x3f >;         /* in zephyr/boards/st/nucleo_l073rz/arduino_r3_connector.dtsi:14 */
		gpio-map = < 0x0 0x0 &gpioa 0x0 0x0 >,
		           < 0x1 0x0 &gpioa 0x1 0x0 >,
		           < 0x2 0x0 &gpioa 0x4 0x0 >,
		           < 0x3 0x0 &gpiob 0x0 0x0 >,
		           < 0x4 0x0 &gpioc 0x1 0x0 >,
		           < 0x5 0x0 &gpioc 0x0 0x0 >,
		           < 0x6 0x0 &gpioa 0x3 0x0 >,
		           < 0x7 0x0 &gpioa 0x2 0x0 >,
		           < 0x8 0x0 &gpioa 0xa 0x0 >,
		           < 0x9 0x0 &gpiob 0x3 0x0 >,
		           < 0xa 0x0 &gpiob 0x5 0x0 >,
		           < 0xb 0x0 &gpiob 0x4 0x0 >,
		           < 0xc 0x0 &gpiob 0xa 0x0 >,
		           < 0xd 0x0 &gpioa 0x8 0x0 >,
		           < 0xe 0x0 &gpioa 0x9 0x0 >,
		           < 0xf 0x0 &gpioc 0x7 0x0 >,
		           < 0x10 0x0 &gpiob 0x6 0x0 >,
		           < 0x11 0x0 &gpioa 0x7 0x0 >,
		           < 0x12 0x0 &gpioa 0x6 0x0 >,
		           < 0x13 0x0 &gpioa 0x5 0x0 >,
		           < 0x14 0x0 &gpiob 0x9 0x0 >,
		           < 0x15 0x0 &gpiob 0x8 0x0 >;    /* in zephyr/boards/st/nucleo_l073rz/arduino_r3_connector.dtsi:15 */
	};

	/* node '/st-morpho-header' defined in zephyr/boards/st/nucleo_l073rz/st_morpho_connector.dtsi:10 */
	st_morpho_header: st-morpho-header {
		compatible = "st-morpho-header";        /* in zephyr/boards/st/nucleo_l073rz/st_morpho_connector.dtsi:11 */
		#gpio-cells = < 0x2 >;                  /* in zephyr/boards/st/nucleo_l073rz/st_morpho_connector.dtsi:12 */
		gpio-map-mask = < 0xff 0x0 >;           /* in zephyr/boards/st/nucleo_l073rz/st_morpho_connector.dtsi:13 */
		gpio-map-pass-thru = < 0x0 0x7f >;      /* in zephyr/boards/st/nucleo_l073rz/st_morpho_connector.dtsi:14 */
		gpio-map = < 0x0 0x0 &gpioc 0xa 0x0 >,
		           < 0x1 0x0 &gpioc 0xb 0x0 >,
		           < 0x2 0x0 &gpioc 0xc 0x0 >,
		           < 0x3 0x0 &gpiod 0x2 0x0 >,
		           < 0xc 0x0 &gpioa 0xd 0x0 >,
		           < 0xe 0x0 &gpioa 0xe 0x0 >,
		           < 0x10 0x0 &gpioa 0xf 0x0 >,
		           < 0x14 0x0 &gpiob 0x7 0x0 >,
		           < 0x16 0x0 &gpioc 0xd 0x0 >,
		           < 0x18 0x0 &gpioc 0xe 0x0 >,
		           < 0x1a 0x0 &gpioc 0xf 0x0 >,
		           < 0x1b 0x0 &gpioa 0x0 0x0 >,
		           < 0x1c 0x0 &gpioh 0x0 0x0 >,
		           < 0x1d 0x0 &gpioa 0x1 0x0 >,
		           < 0x1e 0x0 &gpioh 0x1 0x0 >,
		           < 0x1f 0x0 &gpioa 0x4 0x0 >,
		           < 0x21 0x0 &gpiob 0x0 0x0 >,
		           < 0x22 0x0 &gpioc 0x2 0x0 >,
		           < 0x23 0x0 &gpioc 0x1 0x0 >,
		           < 0x24 0x0 &gpioc 0x3 0x0 >,
		           < 0x25 0x0 &gpioc 0x0 0x0 >,
		           < 0x48 0x0 &gpioc 0x9 0x0 >,
		           < 0x49 0x0 &gpioc 0x8 0x0 >,
		           < 0x4a 0x0 &gpiob 0x8 0x0 >,
		           < 0x4b 0x0 &gpioc 0x6 0x0 >,
		           < 0x4c 0x0 &gpiob 0x9 0x0 >,
		           < 0x4d 0x0 &gpioc 0x5 0x0 >,
		           < 0x52 0x0 &gpioa 0x5 0x0 >,
		           < 0x53 0x0 &gpioa 0xc 0x0 >,
		           < 0x54 0x0 &gpioa 0x6 0x0 >,
		           < 0x55 0x0 &gpioa 0xb 0x0 >,
		           < 0x56 0x0 &gpioa 0x7 0x0 >,
		           < 0x57 0x0 &gpiob 0xc 0x0 >,
		           < 0x58 0x0 &gpiob 0x6 0x0 >,
		           < 0x59 0x0 &gpiob 0xb 0x0 >,
		           < 0x5a 0x0 &gpioc 0x7 0x0 >,
		           < 0x5c 0x0 &gpioa 0x9 0x0 >,
		           < 0x5d 0x0 &gpiob 0x2 0x0 >,
		           < 0x5e 0x0 &gpioa 0x8 0x0 >,
		           < 0x5f 0x0 &gpiob 0x1 0x0 >,
		           < 0x60 0x0 &gpiob 0xa 0x0 >,
		           < 0x61 0x0 &gpiob 0xf 0x0 >,
		           < 0x62 0x0 &gpiob 0x4 0x0 >,
		           < 0x63 0x0 &gpiob 0xe 0x0 >,
		           < 0x64 0x0 &gpiob 0x5 0x0 >,
		           < 0x65 0x0 &gpiob 0xd 0x0 >,
		           < 0x66 0x0 &gpiob 0x3 0x0 >,
		           < 0x68 0x0 &gpioa 0xa 0x0 >,
		           < 0x69 0x0 &gpioc 0x4 0x0 >,
		           < 0x6a 0x0 &gpioa 0x2 0x0 >,
		           < 0x6c 0x0 &gpioa 0x3 0x0 >; /* in zephyr/boards/st/nucleo_l073rz/st_morpho_connector.dtsi:15 */
	};

	/* node '/leds' defined in zephyr/boards/st/nucleo_l073rz/nucleo_l073rz.dts:26 */
	leds: leds {
		compatible = "gpio-leds"; /* in zephyr/boards/st/nucleo_l073rz/nucleo_l073rz.dts:27 */

		/* node '/leds/led_2' defined in zephyr/boards/st/nucleo_l073rz/nucleo_l073rz.dts:29 */
		green_led_2: led_2 {
			gpios = < &gpioa 0x5 0x0 >; /* in zephyr/boards/st/nucleo_l073rz/nucleo_l073rz.dts:30 */
			label = "User LD2";         /* in zephyr/boards/st/nucleo_l073rz/nucleo_l073rz.dts:31 */
		};
	};

	/* node '/gpio_keys' defined in zephyr/boards/st/nucleo_l073rz/nucleo_l073rz.dts:35 */
	gpio_keys {
		compatible = "gpio-keys"; /* in zephyr/boards/st/nucleo_l073rz/nucleo_l073rz.dts:36 */

		/* node '/gpio_keys/button' defined in zephyr/boards/st/nucleo_l073rz/nucleo_l073rz.dts:38 */
		user_button: button {
			label = "User";             /* in zephyr/boards/st/nucleo_l073rz/nucleo_l073rz.dts:39 */
			gpios = < &gpioc 0xd 0x1 >; /* in zephyr/boards/st/nucleo_l073rz/nucleo_l073rz.dts:40 */
			zephyr,code = < 0xb >;      /* in zephyr/boards/st/nucleo_l073rz/nucleo_l073rz.dts:41 */
		};
	};

	/* node '/pwmleds' defined in zephyr/boards/st/nucleo_l073rz/nucleo_l073rz.dts:45 */
	pwmleds: pwmleds {
		compatible = "pwm-leds"; /* in zephyr/boards/st/nucleo_l073rz/nucleo_l073rz.dts:46 */
		status = "disabled";     /* in zephyr/boards/st/nucleo_l073rz/nucleo_l073rz.dts:48 */

		/* node '/pwmleds/green_pwm_led' defined in zephyr/boards/st/nucleo_l073rz/nucleo_l073rz.dts:50 */
		green_pwm_led: green_pwm_led {
			pwms = < &pwm2 0x1 0x1312d00 0x0 >; /* in zephyr/boards/st/nucleo_l073rz/nucleo_l073rz.dts:51 */
		};
	};
};
